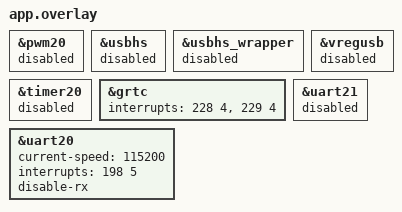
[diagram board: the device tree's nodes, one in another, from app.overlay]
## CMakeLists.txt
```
cmake_minimum_required(VERSION 3.20.0)

# NCS 3.4.1 needs Seeed's external board definitions for this XIAO.
# Board roots must be added before find_package(Zephyr).
list(APPEND BOARD_ROOT
    "${CMAKE_CURRENT_SOURCE_DIR}/../../third_party/platform-seeedboards/zephyr/nrf"
)

# NCS 3.4.1's nrf_security caches these strings without Kconfig quotes.
# On reconfigure, Zephyr mistakes them for command-line Kconfig overrides.
# Discard those malformed entries; Kconfig reloads the configured values.
# Preserve correctly quoted overrides supplied explicitly by the user.
foreach(symbol IN ITEMS
    CONFIG_MBEDTLS_CONFIG_FILE
    CONFIG_TF_PSA_CRYPTO_CONFIG_FILE
    CONFIG_TF_PSA_CRYPTO_USER_CONFIG_FILE
)
    if(DEFINED CACHE{${symbol}} AND NOT "$CACHE{${symbol}}" MATCHES "^\".*\"$")
        unset(${symbol} CACHE)
    endif()
endforeach()

find_package(Zephyr REQUIRED HINTS $ENV{ZEPHYR_BASE})
project(xiao_wireless_benchmark)

target_include_directories(app PRIVATE include)
target_sources(app PRIVATE
    src/main.c
    src/esb_transport.c
    src/link_state_machine.c
    src/benchmark.c
    src/status_telemetry.c
)
# Treat application warnings as errors without imposing this on the Nordic SDK.
target_compile_options(app PRIVATE -Wall -Wextra -Werror)
```

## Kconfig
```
mainmenu "XIAO 4 Mbit/s ESB benchmark"

# Seeed also declares UART_CONSOLE outside Zephyr's CONSOLE menu, with a
# default of y when SERIAL is enabled. With CONSOLE=n its user prompt is
# hidden, so prj.conf alone cannot override that default. Put this default
# first to keep the dedicated telemetry UART free of a console backend.
config UART_CONSOLE
	default n

source "Kconfig.zephyr"

choice BENCHMARK_ROLE

	prompt "Role of this board"
	default BENCHMARK_TRANSMITTER

config BENCHMARK_TRANSMITTER
	bool "Mouse-side transmitter (PTX)"

config BENCHMARK_RECEIVER
	bool "Dongle-side receiver (PRX)"

endchoice

config BENCHMARK_RF_CHANNEL
	int "Fixed ESB RF channel (2400 MHz + channel)"
	range 0 80
	default 40
	help
	  Both builds must use the same channel. This evaluation has no hopping,
	  encryption, or production pairing; keep unrelated test pairs apart.
```

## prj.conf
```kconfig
# The application owns the radio. Bluetooth and USB are not part of this test.
CONFIG_ESB=y
CONFIG_ESB_CLOCK_INIT=y
CONFIG_CLOCK_CONTROL=y
CONFIG_ESB_MAX_PAYLOAD_LENGTH=32
CONFIG_ESB_PIPE_COUNT=1
CONFIG_ESB_TX_FIFO_SIZE=8
CONFIG_ESB_RX_FIFO_SIZE=16
CONFIG_ESB_SYS_TIMER10=y
CONFIG_NRFX_TIMER=y

# Keep symbols and useful locals for RAM inspection. Do not benchmark while halted.
CONFIG_DEBUG_OPTIMIZATIONS=y
CONFIG_DEBUG_THREAD_INFO=y
CONFIG_ASSERT=y
CONFIG_MAIN_STACK_SIZE=4096
CONFIG_GPIO=y
CONFIG_ENTROPY_GENERATOR=y

# Keep CPU/peripheral wake latency short during this timing experiment. This
# consumes extra power: these measurements are not a battery-life benchmark.
CONFIG_SOC_NRF_FORCE_CONSTLAT=y
CONFIG_NRF_SYS_EVENT=y
CONFIG_NRF_SYS_EVENT_GRTC_CHAN_CNT=0

# Low-rate status uses UART20 EasyDMA directly, outside the radio callbacks.
# Keep its pins/peripheral active to avoid repeated IRQ-locked power transitions.
CONFIG_SERIAL=y
CONFIG_UART_ASYNC_API=y
CONFIG_UART_20_ASYNC=y
CONFIG_UART_20_NRF_ASYNC_LOW_POWER=n
# No per-packet logging: its cost would swamp a 125 us schedule.
CONFIG_LOG=n
# UART20 has one owner. Do not let a console/log backend interleave bytes.
CONFIG_CONSOLE=n
CONFIG_UART_CONSOLE=n
```

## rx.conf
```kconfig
# Flash this image onto the dongle-side evaluation board.
CONFIG_BENCHMARK_RECEIVER=y
```

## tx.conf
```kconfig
# Flash this image onto the mouse-side evaluation board.
CONFIG_BENCHMARK_TRANSMITTER=y
```

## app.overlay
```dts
/* The blue LED is a GPIO heartbeat; no PWM driver should claim it. */
&pwm20 {
	status = "disabled";
};

/* V1.0 has no Nordic USB connection. The SAMD11 remains the debug bridge. */
&usbhs {
	status = "disabled";
};
&usbhs_wrapper {
	status = "disabled";
};
&vregusb {
	status = "disabled";
};

/* TIMER20 is accessed directly through nrfx, so leave its Zephyr driver off.
 * ESB owns TIMER10; the operating system owns GRTC. Do not share those timers.
 */
&timer20 {
	status = "disabled";
};

/* On this SoC the application's GRTC IRQs are GRTC_2/3 (228/229).
 * Keep kernel clock bookkeeping below RADIO (1), ESB events (2), and our
 * cadence timer (3), so a control-thread wakeup cannot needlessly delay RF.
 */
&grtc {
	interrupts = <228 4>, <229 4>;
};

/* V1.0 UART20 is wired through a level shifter to the SAMD11 USB-CDC bridge.
 * Its low-priority DMA completion must not preempt radio/cadence/clock work.
 * This telemetry module only transmits; it never starts a UART RX DMA/timer.
 */
&uart20 {
	status = "okay";
	current-speed = <115200>;
	interrupts = <198 5>;
	disable-rx;
};

/* UART21 is the separate D6/D7 header UART, unused in this experiment. */
&uart21 {
	status = "disabled";
};
```

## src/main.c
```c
#include <zephyr/drivers/gpio.h>
#include <zephyr/kernel.h>

#include "link_state_machine.h"
#include "status_telemetry.h"

static const struct gpio_dt_spec led = GPIO_DT_SPEC_GET(DT_ALIAS(led0), gpios);

/* Keep main as glue: modules own radio, connection management, and measurements.
 * The slow heartbeat remains visible without opening a serial monitor.
 * A solid LED indicates an initialization/runtime fault.
 */
int main(void)
{
	bool led_ready = gpio_is_ready_dt(&led) &&
			 gpio_pin_configure_dt(&led, GPIO_OUTPUT_INACTIVE) == 0;
	int telemetry_error = status_telemetry_init();
	int err = link_state_machine_init();
	uint32_t last_toggle_ms = 0;
	bool illuminated = false;

	while (true) {
		if (err == 0) {
			link_state_machine_process();
		}
		if (telemetry_error == 0) {
			status_telemetry_process();
		}
		uint32_t now_ms = k_uptime_get_32();

		if (led_ready && (now_ms - last_toggle_ms >= 500U)) {
			last_toggle_ms = now_ms;
			illuminated = !illuminated;
			gpio_pin_set_dt(&led, telemetry_error != 0 ||
				       g_link_status.state == LINK_FAULT ||
				       illuminated);
		}
		/* This sleep services only slow control. TIMER20 schedules data. */
		k_msleep(10);
	}
	return 0;
}
```

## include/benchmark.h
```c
#ifndef WIRELESS_BENCHMARK_H_
#define WIRELESS_BENCHMARK_H_

#include <stdbool.h>
#include <stdint.h>

#ifdef __cplusplus
extern "C" {
#endif

#define BENCHMARK_RESULT_CAPACITY 25U
#define BENCHMARK_PACKET_COUNT 1000000U
#define BENCHMARK_PERIOD_US 125U
#define BENCHMARK_PAYLOAD_BYTES 16U
#define BENCHMARK_LATE_THRESHOLD_US 10U
#define BENCHMARK_GAP_BUCKETS 6U

/*
 * One run's debugger-friendly summary. Counters are 64-bit so arithmetic such
 * as packet_count * 1,000,000 does not overflow a 32-bit intermediate.
 *
 * The receiver accepts increasing sequence numbers. ESB preserves packet
 * order, so an equal sequence is a duplicate and an older sequence is counted
 * as out-of-order/late. This deliberately avoids a million-packet bitmap.
 *
 * Time values are LOCAL software callback timestamps in microseconds, not
 * synchronized clocks or hardware measurements of radio airtime/latency.
 */
struct benchmark_result {
	uint32_t run_id;
	uint32_t expected_packets;
	uint32_t first_sequence;
	uint32_t last_sequence;
	uint8_t transmitter;
	uint8_t completed;
	uint16_t reserved;
	uint64_t first_activity_us;
	uint64_t last_activity_us;
	uint64_t elapsed_us;

	uint64_t tx_scheduled_slots;
	uint64_t tx_submitted_packets;
	uint64_t tx_busy_drops;
	uint64_t tx_submit_errors;
	uint64_t tx_successes;
	uint64_t tx_failures;
	uint64_t tx_missed_deadlines;
	uint64_t tx_late_slots;
	uint64_t tx_lateness_sum_us;
	uint64_t tx_lateness_max_us;

	uint64_t rx_unique_packets;
	uint64_t rx_duplicate_packets;
	uint64_t rx_out_of_order_packets;
	uint64_t rx_out_of_range_packets;
	/* Live: missing through last_sequence; finished: includes the entire tail. */
	uint64_t rx_missing_packets;
	uint64_t rx_gap_count;
	uint64_t rx_gap_min_us;
	uint64_t rx_gap_max_us;
	uint64_t rx_gap_sum_us;
	/* Buckets: <=125, <=150, <=250, <=500, <=1000, and >1000 us. */
	uint64_t rx_gap_histogram[BENCHMARK_GAP_BUCKETS];

	/*
	 * Cadence is (timestamped_samples - 1) / elapsed: TX opportunities,
	 * including skipped slots, or RX accepted unique packets. millihertz
	 * preserves three decimal places without floating-point code in IRQs.
	 * TX bulk skips use their observation time, so RX cadence is the useful
	 * delivered-packet measurement, especially after a debugger pause.
	 */
	uint64_t packet_rate_millihz;
	/* RX payload goodput excludes the first sample's unobserved interval. */
	uint64_t payload_goodput_bps;
};

/*
 * Result publication uses an odd/even generation: an odd value means finish
 * is publishing; an even value means its result/average/metadata are ready.
 * result_generation[index] == 0 means that ring entry has never been used.
 * Otherwise it is the monotonically increasing recorded-run number.
 */
struct benchmark_metadata {
	uint32_t publication_generation;
	uint32_t write_index;
	uint32_t valid_results;
	uint32_t running;
	uint64_t runs_recorded;
	uint64_t runs_completed;
	uint64_t average_count;
	uint64_t result_generation[BENCHMARK_RESULT_CAPACITY];
};

/*
 * A small, coherent snapshot for periodic status reporting. Per-run counters
 * describe the current run (or its frozen result after finish). tx_total and
 * rx_total count successful data TX and accepted unique RX packets since boot;
 * they survive run changes so a one-second delta remains useful at boundaries.
 * ESB control traffic is deliberately excluded from these packet totals.
 */
struct benchmark_counters {
	uint32_t run_id;
	bool running;
	uint32_t tx_sent;
	uint32_t rx_received;
	uint32_t rx_missing;
	uint32_t tx_busy;
	uint32_t tx_missed;
	uint32_t tx_errors;
	uint64_t tx_total;
	uint64_t rx_total;
	uint64_t recorded_runs;
};

/*
 * These names intentionally remain global and volatile for VS Code/GDB.
 * The ring includes aborted runs. The average includes every completed run
 * since boot, even after its individual ring entry has been overwritten.
 *
 * Every numeric average field is an arithmetic mean of per-run fields:
 * histogram bins, per-run minima/maxima, and derived rates are averaged too.
 * It is NOT a pooled histogram, global extremum, or duration-weighted rate.
 * IDs, sequence numbers, and absolute timestamps are zero in the average;
 * transmitter is 2 if completed runs include both device roles.
 */
extern volatile struct benchmark_result
	g_benchmark_results[BENCHMARK_RESULT_CAPACITY];
extern volatile struct benchmark_result g_benchmark_average;
extern volatile struct benchmark_result g_benchmark_current;
extern volatile struct benchmark_metadata g_benchmark_metadata;

/* Start a run from thread context; expected_packets == 0 leaves it stopped. */
void benchmark_begin(uint32_t run_id, bool transmitter,
		     uint32_t expected_packets);

/* Record one scheduled TX opportunity, even when submitting it failed. */
void benchmark_tx_slot(uint32_t sequence, uint64_t now_us, int submit_result,
		       uint32_t late_us);

/*
 * Record missed opportunities in constant time; no catch-up packets are sent.
 * late_us is lateness of first_sequence at now_us; each subsequent skipped
 * opportunity is one BENCHMARK_PERIOD_US newer. The caller must report each
 * sequence exactly once, either here or through benchmark_tx_slot().
 */
void benchmark_tx_skip(uint32_t first_sequence, uint32_t count,
		       uint64_t now_us, uint32_t late_us);

/* Record ESB completion. With no ACK, success means transmitted, not received. */
void benchmark_tx_complete(bool success);

/* Record one received packet after the caller has validated its run ID. */
void benchmark_rx(uint32_t sequence, uint64_t now_us);

/*
 * Stop and publish from THREAD context after draining transport callbacks.
 * completed means the run reached its agreed end, not that delivery was
 * lossless. now_us is a fallback for a run with no timestamped activity.
 */
void benchmark_finish(bool completed, uint64_t now_us);

/* Return whether callbacks currently contribute to a run. */
bool benchmark_is_running(void);

/* Copy only compact counters under a short IRQ lock; output must be non-NULL. */
void benchmark_get_counters(struct benchmark_counters *counters);

/*
 * Copy the latest recorded run, including aborted runs, without locking IRQs
 * across the large result structure. generation is its recorded-run number.
 * Return false if no result exists or publication overlaps the copy; the caller
 * should retry on its next reporting pass instead of spinning. Both outputs
 * must be non-NULL and remain unchanged on failure.
 */
bool benchmark_get_latest_result(struct benchmark_result *result,
				 uint64_t *generation);

#ifdef __cplusplus
}
#endif

#endif /* WIRELESS_BENCHMARK_H_ */
```

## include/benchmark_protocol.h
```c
#ifndef BENCHMARK_PROTOCOL_H
#define BENCHMARK_PROTOCOL_H

#include <stdbool.h>
#include <stddef.h>
#include <stdint.h>
#include <zephyr/sys/byteorder.h>

#define BENCHMARK_PACKET_COUNT 1000000U
#define BENCHMARK_PERIOD_US 125U
#define BENCHMARK_DATA_SIZE 16U
#define BENCHMARK_CONTROL_SIZE 24U
#define BENCHMARK_PROTOCOL_VERSION 1U

enum benchmark_packet_kind {
	PACKET_HELLO = 1,
	PACKET_READY,
	PACKET_START,
	PACKET_ARMED,
	PACKET_FINISH,
	PACKET_QUERY,
	PACKET_SUMMARY,
	PACKET_MOUSE = 0x80,
};

/* This is an in-memory representation, not an over-the-air C struct. Explicit
 * little-endian encoding avoids padding, alignment, and compiler ABI surprises.
 */
struct benchmark_control {
	enum benchmark_packet_kind kind;
	uint32_t run_id;
	uint32_t received;
	uint32_t missing;
	bool completed;
};

/* Encode the fixed test contract as well as the control message's variable data. */
static inline void benchmark_control_encode(uint8_t *data,
					    const struct benchmark_control *message)
{
	data[0] = message->kind;
	data[1] = BENCHMARK_PROTOCOL_VERSION;
	sys_put_le32(message->run_id, &data[2]);
	sys_put_le32(BENCHMARK_PACKET_COUNT, &data[6]);
	sys_put_le16(BENCHMARK_PERIOD_US, &data[10]);
	data[12] = BENCHMARK_DATA_SIZE;
	data[13] = 4; /* 4 Mbit/s proprietary PHY, not Bluetooth. */
	data[14] = 1; /* Motion packets deliberately request no ACK. */
	sys_put_le32(message->received, &data[15]);
	sys_put_le32(message->missing, &data[19]);
	data[23] = message->completed;
}

/* Reject peers using a different contract before accepting a run or its result. */
static inline bool benchmark_control_decode(const uint8_t *data, size_t length,
					    struct benchmark_control *message)
{
	if (length != BENCHMARK_CONTROL_SIZE || data[0] < PACKET_HELLO ||
	    data[0] > PACKET_SUMMARY || data[1] != BENCHMARK_PROTOCOL_VERSION ||
	    sys_get_le32(&data[6]) != BENCHMARK_PACKET_COUNT ||
	    sys_get_le16(&data[10]) != BENCHMARK_PERIOD_US ||
	    data[12] != BENCHMARK_DATA_SIZE || data[13] != 4 || data[14] != 1 ||
	    data[23] > 1) {
		return false;
	}
	message->kind = data[0];
	message->run_id = sys_get_le32(&data[2]);
	message->received = sys_get_le32(&data[15]);
	message->missing = sys_get_le32(&data[19]);
	message->completed = data[23] != 0;
	return true;
}

/* Create a reproducible spoof mouse report with a 32-bit run and slot sequence.
 * Bytes 9..15 match the seven mouse data bytes in your HID descriptor. The ESB
 * radio appends CRC16 separately; no extra application CRC is needed here.
 */
static inline void benchmark_mouse_encode(uint8_t *data, uint32_t run_id,
					 uint32_t sequence)
{
	data[0] = PACKET_MOUSE;
	sys_put_le32(run_id, &data[1]);
	sys_put_le32(sequence, &data[5]);
	data[9] = (sequence / 8000U) & 0x1fU; /* Five fake buttons. */
	sys_put_le16((uint16_t)(int16_t)((int32_t)(sequence % 201U) - 100), &data[10]);
	sys_put_le16((uint16_t)(int16_t)(100 - (int32_t)(sequence % 201U)), &data[12]);
	data[14] = 0; /* Wheel. */
	data[15] = 0; /* Horizontal pan. */
}

#endif
```

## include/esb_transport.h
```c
/*
 * The transport owns Nordic ESB and its queues. Protocol and benchmark code
 * exchange byte strings here without depending on ESB's payload structures.
 */
#ifndef ESB_TRANSPORT_H_
#define ESB_TRANSPORT_H_

#include <stdbool.h>
#include <stddef.h>
#include <stdint.h>

#define ESB_TRANSPORT_MAX_PAYLOAD 32U

struct esb_transport_callbacks {
	/* Called in ESB event interrupt context; data is valid only in this call. */
	void (*received)(const uint8_t *data, size_t length, uint64_t now_us);
	/* No-ACK success means transmitted, not confirmed reception by the peer. */
	void (*transmitted)(bool success);
};

/* Initialize a fixed PTX or PRX role, 4 Mbps, CRC16 and the test RF address. */
int esb_transport_init(bool transmitter,
		       const struct esb_transport_callbacks *callbacks);

/*
 * Submit one PTX payload. A busy transmitter returns -EBUSY instead of building
 * a queue of old mouse samples. Safe from main or the benchmark timer ISR.
 */
int esb_transport_send(const uint8_t *data, size_t length, bool request_ack);

/*
 * Replace the PRX's next ACK payload during a control phase. The reply is sent
 * in response to a FUTURE request; it cannot amend an ACK already on the air.
 * Retry -EBUSY from main after the current ACK finishes. This operation briefly
 * pauses reception and must not be called during a timed data run.
 */
int esb_transport_receiver_queue_reply(const uint8_t *data, size_t length);

/* Return whether a PTX has finished its previous packet and can send another. */
bool esb_transport_is_idle(void);

/* Clear stale packets between control phases; never call during a timed run. */
int esb_transport_reset_queues(void);

#endif /* ESB_TRANSPORT_H_ */
```

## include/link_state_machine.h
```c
#ifndef LINK_STATE_MACHINE_H
#define LINK_STATE_MACHINE_H

#include <stdbool.h>
#include <stdint.h>

enum link_state {
	LINK_BOOT,
	LINK_DISCOVERING,
	LINK_NEGOTIATING,
	LINK_ARMED,
	LINK_RUNNING,
	LINK_DRAINING,
	LINK_WAIT_SUMMARY,
	LINK_PAUSE,
	LINK_FAULT,
};

/* Deliberately public debugger view. Operational state remains private to the
 * module. Pause before inspecting 64-bit fields on this 32-bit CPU.
 */
struct link_debug_status {
	enum link_state state;
	bool transmitter;
	uint32_t run_id;
	int last_error;
	uint32_t rejected_packets;
	uint32_t control_queue_overflows;
	uint32_t control_tx_failures;
	uint32_t reconnects;
	uint32_t next_sequence;
	uint32_t remote_received;
	uint32_t remote_missing;
	bool remote_completed;
	bool remote_summary_valid;
	uint64_t last_data_rx_us;
};

extern volatile struct link_debug_status g_link_status;

/* Initialize the fixed PTX/PRX role selected by this image's Kconfig. */
int link_state_machine_init(void);

/* Service control traffic and timeouts from the main thread, about every 10 ms. */
void link_state_machine_process(void);

/* Copy the compact debugger view coherently while radio callbacks are active. */
void link_state_machine_get_status(struct link_debug_status *status);

#endif
```

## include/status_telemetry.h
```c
#ifndef STATUS_TELEMETRY_H_
#define STATUS_TELEMETRY_H_

#include <stdbool.h>

/* Debugger switch for comparing RF performance with reporting enabled/disabled.
 * An already queued DMA line may finish after this is cleared. No reset needed.
 */
extern volatile bool g_status_telemetry_enabled;

/* Initialize the SAMD11 bridge UART for asynchronous, transmit-only status. */
int status_telemetry_init(void);

/* Report state changes, finished runs, and one-second counters from main only. */
void status_telemetry_process(void);

#endif /* STATUS_TELEMETRY_H_ */
```

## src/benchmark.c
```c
#include "benchmark.h"

#include <errno.h>
#include <stddef.h>
#include <string.h>

#include <zephyr/irq.h>

volatile struct benchmark_result g_benchmark_results[BENCHMARK_RESULT_CAPACITY];
volatile struct benchmark_result g_benchmark_average;
volatile struct benchmark_result g_benchmark_current;
volatile struct benchmark_metadata g_benchmark_metadata;

/*
 * A separate exact sum prevents recursive integer averaging from steadily
 * rounding the running average toward zero. All divisions happen at finish,
 * outside the time-sensitive radio/timer callbacks.
 */
#define AVERAGED_FIELDS(X)                   \
	X(expected_packets)                  \
	X(elapsed_us)                        \
	X(tx_scheduled_slots)                \
	X(tx_submitted_packets)              \
	X(tx_busy_drops)                     \
	X(tx_submit_errors)                  \
	X(tx_successes)                      \
	X(tx_failures)                       \
	X(tx_missed_deadlines)               \
	X(tx_late_slots)                     \
	X(tx_lateness_sum_us)                \
	X(tx_lateness_max_us)                \
	X(rx_unique_packets)                \
	X(rx_duplicate_packets)             \
	X(rx_out_of_order_packets)          \
	X(rx_out_of_range_packets)          \
	X(rx_missing_packets)               \
	X(rx_gap_count)                     \
	X(rx_gap_min_us)                    \
	X(rx_gap_max_us)                    \
	X(rx_gap_sum_us)                    \
	X(packet_rate_millihz)              \
	X(payload_goodput_bps)

struct benchmark_totals {
#define DECLARE_TOTAL(field) uint64_t field;
	AVERAGED_FIELDS(DECLARE_TOTAL)
#undef DECLARE_TOTAL
	uint64_t rx_gap_histogram[BENCHMARK_GAP_BUCKETS];
};

static struct benchmark_totals average_totals;
static bool have_activity;
static uint8_t averaged_role;
/* These boot-lifetime totals cannot jump backward when begin resets a run. */
static uint64_t lifetime_tx_successes;
static uint64_t lifetime_rx_unique_packets;

/* Identify one inter-arrival bucket without division or floating point. */
static size_t gap_bucket(uint64_t gap_us)
{
	if (gap_us <= 125U) {
		return 0U;
	}
	if (gap_us <= 150U) {
		return 1U;
	}
	if (gap_us <= 250U) {
		return 2U;
	}
	if (gap_us <= 500U) {
		return 3U;
	}
	if (gap_us <= 1000U) {
		return 4U;
	}
	return 5U;
}

/* Update sample bounds while the caller holds the short IRQ critical section. */
static void record_activity(uint32_t sequence, uint64_t now_us)
{
	if (!have_activity) {
		g_benchmark_current.first_activity_us = now_us;
		g_benchmark_current.first_sequence = sequence;
		have_activity = true;
	}
	g_benchmark_current.last_activity_us = now_us;
	g_benchmark_current.last_sequence = sequence;
	g_benchmark_current.elapsed_us = now_us - g_benchmark_current.first_activity_us;
}

/* Accumulate one slot's scheduling jitter while interrupts are locked. */
static void record_lateness(uint32_t late_us)
{
	g_benchmark_current.tx_lateness_sum_us += late_us;
	if (late_us > g_benchmark_current.tx_lateness_max_us) {
		g_benchmark_current.tx_lateness_max_us = late_us;
	}
	if (late_us > BENCHMARK_LATE_THRESHOLD_US) {
		g_benchmark_current.tx_late_slots++;
	}
}

/* Start with a fresh live summary; history and its all-run average survive. */
void benchmark_begin(uint32_t run_id, bool transmitter,
		     uint32_t expected_packets)
{
	struct benchmark_result fresh = {
		.run_id = run_id,
		.expected_packets = expected_packets,
		.transmitter = transmitter ? 1U : 0U,
	};
	unsigned int key = irq_lock();

	g_benchmark_current = fresh;
	have_activity = false;
	g_benchmark_metadata.running = expected_packets != 0U;
	irq_unlock(key);
}

/* Count an attempted opportunity separately from an accepted ESB submission. */
void benchmark_tx_slot(uint32_t sequence, uint64_t now_us, int submit_result,
		       uint32_t late_us)
{
	unsigned int key = irq_lock();

	if (!g_benchmark_metadata.running || !g_benchmark_current.transmitter) {
		irq_unlock(key);
		return;
	}
	if (sequence >= g_benchmark_current.expected_packets) {
		g_benchmark_current.tx_submit_errors++;
		irq_unlock(key);
		return;
	}
	record_activity(sequence, now_us);
	g_benchmark_current.tx_scheduled_slots++;
	record_lateness(late_us);
	if (submit_result == 0) {
		g_benchmark_current.tx_submitted_packets++;
	} else if (submit_result == -EBUSY || submit_result == -ENOBUFS ||
		   submit_result == -EAGAIN || submit_result == -ENOMEM) {
		/* Nordic ESB reports a full software FIFO as -ENOMEM. */
		g_benchmark_current.tx_busy_drops++;
	} else {
		g_benchmark_current.tx_submit_errors++;
	}
	irq_unlock(key);
}

/* Summarize a missed block arithmetically, rather than looping in a timer IRQ. */
void benchmark_tx_skip(uint32_t first_sequence, uint32_t count,
		       uint64_t now_us, uint32_t late_us)
{
	unsigned int key = irq_lock();
	uint64_t positive_count;
	uint64_t late_count;
	uint64_t lateness_sum;
	uint32_t remaining;

	if (!g_benchmark_metadata.running || !g_benchmark_current.transmitter ||
	    count == 0U || first_sequence >= g_benchmark_current.expected_packets) {
		irq_unlock(key);
		return;
	}
	remaining = g_benchmark_current.expected_packets - first_sequence;
	if (count > remaining) {
		count = remaining;
	}

	/*
	 * Lateness is max(late_us - index * period, 0). Sum the positive
	 * arithmetic progression, using 64-bit products even for long pauses.
	 */
	positive_count = ((uint64_t)late_us + BENCHMARK_PERIOD_US - 1U) /
			 BENCHMARK_PERIOD_US;
	if (positive_count > count) {
		positive_count = count;
	}
	lateness_sum = positive_count * late_us;
	if (positive_count > 0U) {
		lateness_sum -= BENCHMARK_PERIOD_US * positive_count *
				(positive_count - 1U) / 2U;
	}
	late_count = late_us > BENCHMARK_LATE_THRESHOLD_US ?
		((uint64_t)late_us - BENCHMARK_LATE_THRESHOLD_US +
		 BENCHMARK_PERIOD_US - 1U) / BENCHMARK_PERIOD_US : 0U;
	if (late_count > count) {
		late_count = count;
	}
	if (!have_activity) {
		/* The first observed block still identifies its earliest sequence. */
		record_activity(first_sequence, now_us);
	}
	record_activity(first_sequence + count - 1U, now_us);
	g_benchmark_current.tx_scheduled_slots += count;
	g_benchmark_current.tx_missed_deadlines += count;
	g_benchmark_current.tx_late_slots += late_count;
	g_benchmark_current.tx_lateness_sum_us += lateness_sum;
	if (late_us > g_benchmark_current.tx_lateness_max_us) {
		g_benchmark_current.tx_lateness_max_us = late_us;
	}
	irq_unlock(key);
}

/* ESB no-ACK success proves only that a packet left this transmitter. */
void benchmark_tx_complete(bool success)
{
	unsigned int key = irq_lock();

	if (g_benchmark_metadata.running && g_benchmark_current.transmitter) {
		if (success) {
			g_benchmark_current.tx_successes++;
			lifetime_tx_successes++;
		} else {
			g_benchmark_current.tx_failures++;
		}
	}
	irq_unlock(key);
}

/* Count ordered unique deliveries and their local callback-to-callback gaps. */
void benchmark_rx(uint32_t sequence, uint64_t now_us)
{
	unsigned int key = irq_lock();
	uint64_t gap_us;

	if (!g_benchmark_metadata.running || g_benchmark_current.transmitter) {
		irq_unlock(key);
		return;
	}
	if (sequence >= g_benchmark_current.expected_packets) {
		g_benchmark_current.rx_out_of_range_packets++;
		irq_unlock(key);
		return;
	}
	if (have_activity && sequence <= g_benchmark_current.last_sequence) {
		if (sequence == g_benchmark_current.last_sequence) {
			g_benchmark_current.rx_duplicate_packets++;
		} else {
			/* Older retransmissions cannot be distinguished from reordering. */
			g_benchmark_current.rx_out_of_order_packets++;
		}
		irq_unlock(key);
		return;
	}
	if (have_activity) {
		gap_us = now_us - g_benchmark_current.last_activity_us;
		if (g_benchmark_current.rx_gap_count == 0U ||
		    gap_us < g_benchmark_current.rx_gap_min_us) {
			g_benchmark_current.rx_gap_min_us = gap_us;
		}
		if (gap_us > g_benchmark_current.rx_gap_max_us) {
			g_benchmark_current.rx_gap_max_us = gap_us;
		}
		g_benchmark_current.rx_gap_count++;
		g_benchmark_current.rx_gap_sum_us += gap_us;
		g_benchmark_current.rx_gap_histogram[gap_bucket(gap_us)]++;
	}
	record_activity(sequence, now_us);
	g_benchmark_current.rx_unique_packets++;
	lifetime_rx_unique_packets++;
	/* During a run only losses up through the newest received sequence are
	 * knowable. finish() adds the unreceived tail of the agreed packet count.
	 */
	g_benchmark_current.rx_missing_packets = (uint64_t)sequence + 1U -
						g_benchmark_current.rx_unique_packets;
	irq_unlock(key);
}

/* Derive rates once per run, keeping integer division outside radio IRQs. */
static void finalize_result(struct benchmark_result *result)
{
	uint64_t samples = result->transmitter ? result->tx_scheduled_slots :
						 result->rx_unique_packets;

	result->elapsed_us = result->last_activity_us - result->first_activity_us;
	if (!result->transmitter) {
		/* Includes losses before the first and after the last received packet. */
		result->rx_missing_packets = result->expected_packets -
					    result->rx_unique_packets;
	}
	if (samples > 1U && result->elapsed_us > 0U) {
		/* samples is bounded by the 32-bit expected count, so these fit. */
		result->packet_rate_millihz = (samples - 1U) * UINT64_C(1000000000) /
					    result->elapsed_us;
		if (!result->transmitter) {
			result->payload_goodput_bps = (samples - 1U) *
				BENCHMARK_PAYLOAD_BYTES * 8U * UINT64_C(1000000) /
				result->elapsed_us;
		}
	}
}

/* Add exact totals and return the arithmetic mean of completed run summaries. */
static struct benchmark_result update_average(const struct benchmark_result *result,
					     uint64_t count)
{
	struct benchmark_result average = { .completed = 1U };

	if (count == 1U) {
		averaged_role = result->transmitter;
	} else if (averaged_role != result->transmitter) {
		averaged_role = 2U;
	}
	average.transmitter = averaged_role;
#define ADD_AND_AVERAGE(field)                       \
	average_totals.field += result->field;        \
	average.field = average_totals.field / count;
	AVERAGED_FIELDS(ADD_AND_AVERAGE)
#undef ADD_AND_AVERAGE
	for (size_t index = 0U; index < BENCHMARK_GAP_BUCKETS; index++) {
		average_totals.rx_gap_histogram[index] += result->rx_gap_histogram[index];
		average.rx_gap_histogram[index] =
			average_totals.rx_gap_histogram[index] / count;
	}
	return average;
}

/* Freeze live counters, then publish one ring entry and its all-history mean. */
void benchmark_finish(bool completed, uint64_t now_us)
{
	struct benchmark_result result;
	struct benchmark_result average;
	uint64_t recorded_runs;
	uint64_t completed_runs;
	uint32_t index;
	unsigned int key = irq_lock();

	if (!g_benchmark_metadata.running) {
		irq_unlock(key);
		return;
	}
	g_benchmark_metadata.running = false;
	result = g_benchmark_current;
	if (!have_activity) {
		result.first_activity_us = now_us;
		result.last_activity_us = now_us;
	}
	irq_unlock(key);

	result.completed = completed ? 1U : 0U;
	finalize_result(&result);
	recorded_runs = g_benchmark_metadata.runs_recorded + 1U;
	completed_runs = g_benchmark_metadata.runs_completed + (completed ? 1U : 0U);
	if (completed) {
		average = update_average(&result, completed_runs);
	}

	/*
	 * No callbacks can mutate this stopped run. Publication may copy with
	 * interrupts enabled; debugger consumers check for an even generation
	 * before interpreting a snapshot taken inside this function.
	 */
	g_benchmark_metadata.publication_generation++;
	index = g_benchmark_metadata.write_index;
	g_benchmark_metadata.result_generation[index] = 0U;
	g_benchmark_results[index] = result;
	g_benchmark_current = result;
	if (completed) {
		g_benchmark_average = average;
	}
	g_benchmark_metadata.result_generation[index] = recorded_runs;
	/* The compact telemetry snapshot also reads this 64-bit value on a 32-bit
	 * CPU. Protect this small store so a reporting thread cannot see half of it.
	 */
	key = irq_lock();
	g_benchmark_metadata.runs_recorded = recorded_runs;
	irq_unlock(key);
	g_benchmark_metadata.runs_completed = completed_runs;
	g_benchmark_metadata.average_count = completed_runs;
	g_benchmark_metadata.write_index = (index + 1U) % BENCHMARK_RESULT_CAPACITY;
	if (g_benchmark_metadata.valid_results < BENCHMARK_RESULT_CAPACITY) {
		g_benchmark_metadata.valid_results++;
	}
	g_benchmark_metadata.publication_generation++;
}

/* Read the shared running flag consistently on the single application CPU. */
bool benchmark_is_running(void)
{
	unsigned int key = irq_lock();
	bool running = g_benchmark_metadata.running != 0U;

	irq_unlock(key);
	return running;
}

/* Keep status reporting out of the large per-run summary's IRQ-locked copy. */
void benchmark_get_counters(struct benchmark_counters *counters)
{
	unsigned int key = irq_lock();

	counters->run_id = g_benchmark_current.run_id;
	counters->running = g_benchmark_metadata.running != 0U;
	/* Each normal run has at most one million data slots/packets, so its
	 * counters fit in 32 bits. Lifetime totals remain 64-bit across runs.
	 */
	counters->tx_sent = (uint32_t)g_benchmark_current.tx_successes;
	counters->rx_received = (uint32_t)g_benchmark_current.rx_unique_packets;
	counters->rx_missing = (uint32_t)g_benchmark_current.rx_missing_packets;
	counters->tx_busy = (uint32_t)g_benchmark_current.tx_busy_drops;
	counters->tx_missed = (uint32_t)g_benchmark_current.tx_missed_deadlines;
	counters->tx_errors = (uint32_t)(g_benchmark_current.tx_submit_errors +
					 g_benchmark_current.tx_failures);
	counters->tx_total = lifetime_tx_successes;
	counters->rx_total = lifetime_rx_unique_packets;
	counters->recorded_runs = g_benchmark_metadata.runs_recorded;
	irq_unlock(key);
}

/* Use the publication generation to reject a large copy interrupted by finish. */
bool benchmark_get_latest_result(struct benchmark_result *result,
				 uint64_t *generation)
{
	struct benchmark_result snapshot;
	uint64_t recorded_generation;
	uint32_t before = g_benchmark_metadata.publication_generation;
	uint32_t index;
	uint32_t after;

	if ((before & 1U) != 0U || g_benchmark_metadata.valid_results == 0U) {
		return false;
	}
	index = (g_benchmark_metadata.write_index + BENCHMARK_RESULT_CAPACITY - 1U) %
		BENCHMARK_RESULT_CAPACITY;
	snapshot = g_benchmark_results[index];
	recorded_generation = g_benchmark_metadata.result_generation[index];
	after = g_benchmark_metadata.publication_generation;
	/* All shared publication fields are volatile. If a publisher ran during
	 * this interruptible copy, ignore even a plausible-looking partial result.
	 */
	if (before != after || (after & 1U) != 0U || recorded_generation == 0U) {
		return false;
	}
	*result = snapshot;
	*generation = recorded_generation;
	return true;
}
```

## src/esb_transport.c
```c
/*
 * A deliberately small ESB adapter: one radio owner, one outstanding PTX
 * payload, no allocation, and no logging in either radio interrupt path.
 */
#include "esb_transport.h"

#include <errno.h>
#include <string.h>

#include <esb.h>
#include <hal/nrf_radio.h>
#include <zephyr/irq.h>
#include <zephyr/kernel.h>
#include <zephyr/sys/util.h>

BUILD_ASSERT(CONFIG_ESB_MAX_PAYLOAD_LENGTH >= ESB_TRANSPORT_MAX_PAYLOAD,
	     "The transport requires 32-byte ESB payload storage");
BUILD_ASSERT(CONFIG_ESB_TX_FIFO_SIZE >= 2,
	     "Replacing ACK payloads requires two ESB TX FIFO entries");

static struct esb_transport_callbacks transport_callbacks;
static bool transport_initialized;
static bool transport_transmitter;
static bool transport_tx_busy;

/* Convert the kernel's 64-bit hardware cycle counter to monotonic microseconds. */
static uint64_t transport_now_us(void)
{
	/* On this board the cycle source is GRTC, not the CPU clock or SysTick. */
	return k_cyc_to_us_floor64(k_cycle_get_64());
}

/* Replace an ACK only while the PRX is unambiguously in a receive state. */
static bool receiver_ack_in_progress(void)
{
	nrf_radio_state_t state = nrf_radio_state_get(NRF_RADIO);

	/* Include disable/disabled transitions: hardware shorts may already be
	 * about to ramp TX before the higher-priority radio IRQ has run.
	 */
	return state != NRF_RADIO_STATE_RXRU &&
	       state != NRF_RADIO_STATE_RXIDLE &&
	       state != NRF_RADIO_STATE_RX;
}

/* Deliver short notifications and completely drain ESB's coalesced RX event. */
static void transport_event_handler(const struct esb_evt *event)
{
	switch (event->evt_id) {
	case ESB_EVENT_TX_SUCCESS:
	case ESB_EVENT_TX_FAILED:
		/* PRX also reports TX_SUCCESS when an ACK payload is retired. That
		 * notification does not complete a benchmark transmission.
		 */
		if (transport_transmitter) {
			unsigned int key = irq_lock();
			bool success = event->evt_id == ESB_EVENT_TX_SUCCESS;

			if (!success) {
				/* ESB retains a failed reliable packet at the FIFO head.
				 * Remove it before admitting the next control packet.
				 * ESB sets itself IDLE before issuing TX_FAILED.
				 */
				(void)esb_flush_tx();
			}
			transport_tx_busy = false;
			irq_unlock(key);

			if (transport_callbacks.transmitted != NULL) {
				transport_callbacks.transmitted(success);
			}
		}
		break;

	case ESB_EVENT_RX_RECEIVED: {
		struct esb_payload payload;

		/* ESB event flags are bits, not packet counts: a single callback
		 * can represent several FIFO entries. Always drain the FIFO.
		 */
		while (esb_read_rx_payload(&payload) == 0) {
			uint64_t now_us = transport_now_us();

			if (transport_callbacks.received != NULL) {
				/* This is callback arrival time, not a hardware RF timestamp.
				 * A delayed event IRQ can therefore affect measured jitter.
				 */
				transport_callbacks.received(payload.data, payload.length,
							     now_us);
			}
		}
		break;
	}
	default:
		break;
	}
}

/* Configure both roles identically except for which endpoint initiates a send. */
int esb_transport_init(bool transmitter,
		       const struct esb_transport_callbacks *callbacks)
{
	/* Fixed, intentionally public bench addresses; these are not pairing keys. */
	static const uint8_t base_address_0[4] = {0xA7, 0xC3, 0x56, 0x91};
	static const uint8_t base_address_1[4] = {0xD2, 0x8B, 0x47, 0x69};
	static const uint8_t prefixes[1] = {0xE7};
	struct esb_config config = ESB_DEFAULT_CONFIG;
	int err;

	if (callbacks == NULL) {
		return -EINVAL;
	}
	if (transport_initialized) {
		return -EALREADY;
	}

	transport_callbacks = *callbacks;
	transport_transmitter = transmitter;
	transport_tx_busy = false;
	config.mode = transmitter ? ESB_MODE_PTX : ESB_MODE_PRX;
	config.protocol = ESB_PROTOCOL_ESB_DPL;
	config.bitrate = ESB_BITRATE_4MBPS;
	config.crc = ESB_CRC_16BIT;
	config.selective_auto_ack = true;
	config.use_fast_ramp_up = true;
	config.event_handler = transport_event_handler;
	/* The minimum retransmit delay is validated even for no-ACK data. Keep
	 * the SDK's supported 600 us value; it is not the 125 us data cadence.
	 */
	config.retransmit_delay = 600;
	config.retransmit_count = 3;

	err = esb_init(&config);
	if (err != 0) {
		return err;
	}
	err = esb_set_base_address_0(base_address_0);
	if (err == 0) {
		err = esb_set_base_address_1(base_address_1);
	}
	if (err == 0) {
		err = esb_set_prefixes(prefixes, ARRAY_SIZE(prefixes));
	}
	if (err == 0) {
		err = esb_enable_pipes(BIT(0));
	}
	if (err == 0) {
		err = esb_set_rf_channel(CONFIG_BENCHMARK_RF_CHANNEL);
	}
	if (err == 0 && !transmitter) {
		err = esb_start_rx();
	}
	if (err != 0) {
		esb_disable();
		return err;
	}
	transport_initialized = true;
	return 0;
}

/* Copy one sample into ESB only when there is no older sample waiting to send. */
int esb_transport_send(const uint8_t *data, size_t length, bool request_ack)
{
	struct esb_payload payload = {0};
	unsigned int key;
	int err;

	if (!transport_initialized || !transport_transmitter) {
		return -EACCES;
	}
	if (data == NULL || length == 0 || length > ESB_TRANSPORT_MAX_PAYLOAD) {
		return -EINVAL;
	}
	payload.pipe = 0;
	payload.length = length;
	payload.noack = !request_ack;
	memcpy(payload.data, data, length);

	/* Main and the cadence ISR both call this API. A single critical section
	 * makes the busy test, ownership change and ESB queue insertion atomic.
	 * Radio/event IRQs stay masked only while copying this small payload.
	 */
	key = irq_lock();
	if (transport_tx_busy || !esb_is_idle()) {
		irq_unlock(key);
		return -EBUSY;
	}
	transport_tx_busy = true;
	err = esb_write_payload(&payload);
	if (err != 0) {
		transport_tx_busy = false;
	}
	irq_unlock(key);
	return err;
}

/* Replace stale PRX ACK contents without interrupting an ACK already on air. */
int esb_transport_receiver_queue_reply(const uint8_t *data, size_t length)
{
	struct esb_payload payload = {0};
	unsigned int key;
	int err;
	int restart_err;

	if (!transport_initialized || transport_transmitter) {
		return -EACCES;
	}
	if (data == NULL || length == 0 || length > ESB_TRANSPORT_MAX_PAYLOAD) {
		return -EINVAL;
	}
	payload.pipe = 0;
	payload.length = length;
	memcpy(payload.data, data, length);

	key = irq_lock();
	if (receiver_ack_in_progress()) {
		irq_unlock(key);
		return -EBUSY;
	}
	/* ESB permits queue flushes only in IDLE. PRX normally listens forever,
	 * so a bounded control-phase pause is required before replacing a reply.
	 */
	err = esb_stop_rx();
	if (err == -EALREADY) {
		err = 0;
	}
	if (err == 0) {
		err = esb_flush_tx();
	}
	if (err == 0) {
		err = esb_write_payload(&payload);
	}
	if (err == 0) {
		/* Counter-intuitively, ESB's flush does not clear its per-pipe
		 * "previous ACK carried data" flag. The next NEW request may
		 * retire one queue head before selecting its reply. Two identical
		 * copies make the replacement valid whether that flag is set or
		 * clear; protocol tokens let the peer ignore repeated replies.
		 */
		err = esb_write_payload(&payload);
	}
	restart_err = esb_start_rx();
	irq_unlock(key);
	return err != 0 ? err : restart_err;
}

/* Snapshot the transport's PTX ownership and ESB state as one coherent test. */
bool esb_transport_is_idle(void)
{
	unsigned int key = irq_lock();
	bool idle = transport_initialized && transport_transmitter &&
		    !transport_tx_busy && esb_is_idle();

	irq_unlock(key);
	return idle;
}

/* Empty queues after a completed/aborted run so the next run starts cleanly. */
int esb_transport_reset_queues(void)
{
	unsigned int key;
	int err;
	int restart_err = 0;

	if (!transport_initialized) {
		return -EACCES;
	}
	key = irq_lock();
	if (transport_tx_busy ||
	    (transport_transmitter && !esb_is_idle()) ||
	    (!transport_transmitter && receiver_ack_in_progress())) {
		irq_unlock(key);
		return -EBUSY;
	}
	err = transport_transmitter ? 0 : esb_stop_rx();
	if (err == -EALREADY) {
		err = 0;
	}
	if (err == 0) {
		err = esb_flush_tx();
	}
	if (err == 0) {
		err = esb_flush_rx();
	}
	if (!transport_transmitter) {
		restart_err = esb_start_rx();
	}
	irq_unlock(key);
	return err != 0 ? err : restart_err;
}
```

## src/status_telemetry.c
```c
#include "status_telemetry.h"

#include <errno.h>
#include <inttypes.h>
#include <stddef.h>
#include <zephyr/device.h>
#include <zephyr/drivers/uart.h>
#include <zephyr/kernel.h>
#include <zephyr/sys/atomic.h>
#include <zephyr/sys/printk.h>

#include "benchmark.h"
#include "link_state_machine.h"

#define STATUS_PERIOD_US 1000000ULL
#define STATUS_BUFFER_SIZE 512U

volatile bool g_status_telemetry_enabled = true;

static const struct device *const uart = DEVICE_DT_GET(DT_NODELABEL(uart20));
static const char *const role = IS_ENABLED(CONFIG_BENCHMARK_TRANSMITTER) ?
			       "TX" : "RX";
/* EasyDMA reads this RAM until TX_DONE/TX_ABORTED. Never reuse it while busy. */
static char tx_buffer[STATUS_BUFFER_SIZE];
static atomic_t tx_busy;
static atomic_t tx_aborts;
static uint32_t tx_submit_errors;
static bool banner_sent;
static bool state_reported;
static enum link_state reported_state;
static uint32_t reported_run;
static uint64_t reported_result;
static uint32_t reported_publication;
static uint64_t previous_time_us;
static uint64_t started_us;
static uint64_t previous_tx_total;
static uint64_t previous_rx_total;

/* DMA completion only releases ownership; all formatting stays in main. */
static void uart_event(const struct device *device, struct uart_event *event,
		       void *context)
{
	ARG_UNUSED(device);
	ARG_UNUSED(context);
	if (event->type == UART_TX_ABORTED) {
		atomic_inc(&tx_aborts);
	}
	if (event->type == UART_TX_DONE || event->type == UART_TX_ABORTED) {
		atomic_clear(&tx_busy);
	}
}

/* Give bounds-checked text to DMA without waiting for a host or a free UART. */
static bool send_line(int length)
{
	if (length <= 0 || (size_t)length >= sizeof(tx_buffer)) {
		tx_submit_errors++;
		return false;
	}
	/* Set ownership before submission: completion can interrupt uart_tx(). */
	atomic_set(&tx_busy, 1);
	int err = uart_tx(uart, (const uint8_t *)tx_buffer, (size_t)length,
			 SYS_FOREVER_US);

	if (err != 0) {
		atomic_clear(&tx_busy);
		tx_submit_errors++;
		return false;
	}
	return true;
}

/* Use readable names without indexing beyond the enum on a faulted device. */
static const char *state_name(enum link_state state)
{
	static const char *const names[] = {
		"BOOT", "DISCOVERING", "NEGOTIATING", "ARMED", "RUNNING",
		"DRAINING", "WAIT_SUMMARY", "PAUSE", "FAULT",
	};

	return (unsigned int)state < ARRAY_SIZE(names) ? names[state] : "UNKNOWN";
}

/* Queue an immutable, end-of-run summary before the next periodic status. */
static bool report_result(const struct benchmark_result *result,
			  uint64_t generation)
{
	int length = snprintk(tx_buffer, sizeof(tx_buffer),
		"[%s] RESULT #=%" PRIu64 " run=%08" PRIX32
		" complete=%u tx=%" PRIu64 " rx=%" PRIu64 " lost=%" PRIu64
		" busy=%" PRIu64 " missed=%" PRIu64 " errors=%" PRIu64
		" rate=%" PRIu64 ".%03" PRIu64 "/s max_gap_us=%" PRIu64
		" max_late_us=%" PRIu64 "\r\n",
		role, generation, result->run_id, (unsigned int)result->completed,
		result->tx_successes, result->rx_unique_packets,
		result->rx_missing_packets, result->tx_busy_drops,
		result->tx_missed_deadlines,
		result->tx_submit_errors + result->tx_failures,
		result->packet_rate_millihz / 1000U,
		result->packet_rate_millihz % 1000U, result->rx_gap_max_us,
		result->tx_lateness_max_us);

	return send_line(length);
}

/* Set up TX-only EasyDMA. A missing serial host never prevents radio startup. */
int status_telemetry_init(void)
{
	if (!device_is_ready(uart)) {
		return -ENODEV;
	}
	previous_time_us = k_cyc_to_us_floor64(k_cycle_get_64());
	/* The hardware GRTC counter can survive a core reset. Display time since
	 * this application initialized instead of that counter's absolute value.
	 */
	started_us = previous_time_us;
	return uart_callback_set(uart, uart_event, NULL);
}

/* Report at most one DMA frame per pass, with no queues or blocking calls. */
void status_telemetry_process(void)
{
	struct link_debug_status link;
	struct benchmark_counters counters;
	uint64_t now_us;
	int length;

	if (!g_status_telemetry_enabled || atomic_get(&tx_busy)) {
		return;
	}
	now_us = k_cyc_to_us_floor64(k_cycle_get_64());
	/* Most 10 ms passes need no report. These atomic-width volatile reads
	 * are only change hints; the coherent snapshots below supply the text.
	 * This avoids masking radio interrupts 100 times/second just to discover
	 * unchanged status. An ISR transition after this check is seen next pass.
	 */
	if (banner_sent && state_reported &&
	    g_link_status.state == reported_state &&
	    g_link_status.run_id == reported_run &&
	    g_benchmark_metadata.publication_generation == reported_publication &&
	    now_us - previous_time_us < STATUS_PERIOD_US) {
		return;
	}
	link_state_machine_get_status(&link);
	benchmark_get_counters(&counters);

	if (!banner_sent) {
		length = snprintk(tx_buffer, sizeof(tx_buffer),
			"[%s] XIAO V1 UART20 115200 8N1; ESB 4M; period_us=%u; "
			"status_ms=1000; lost=sequence gaps; TX success != delivery\r\n",
			role, BENCHMARK_PERIOD_US);
		banner_sent = send_line(length);
		return;
	}
	if (counters.recorded_runs > reported_result) {
		struct benchmark_result result;
		uint64_t generation;

		/* The large result is copied without an IRQ lock. A publication
		 * overlap is retried on the next main pass, never in a busy loop.
		 */
		if (benchmark_get_latest_result(&result, &generation) &&
		    report_result(&result, generation)) {
			reported_result = generation;
			/* Only main publishes results, so this generation cannot
			 * advance between the result snapshot and this assignment.
			 */
			reported_publication =
				g_benchmark_metadata.publication_generation;
		}
		return;
	}
	if (!state_reported || link.state != reported_state ||
	    link.run_id != reported_run) {
		length = snprintk(tx_buffer, sizeof(tx_buffer),
			"[%s] LINK state=%s run=%08" PRIX32 " error=%d reconnects=%"
			PRIu32 " peer_last_rx=%" PRIu32 " peer_last_lost=%" PRIu32
			" peer_summary_valid=%u\r\n", role, state_name(link.state),
			link.run_id, link.last_error, link.reconnects,
			link.remote_received, link.remote_missing,
			(unsigned int)link.remote_summary_valid);
		if (send_line(length)) {
			state_reported = true;
			reported_state = link.state;
			reported_run = link.run_id;
		}
		return;
	}
	uint64_t elapsed_us = now_us - previous_time_us;

	if (elapsed_us < STATUS_PERIOD_US) {
		return;
	}
	/* Lifetime totals never reset at a run boundary. Divide by the actual
	 * sample window: the 10 ms main loop is intentionally not a precise clock.
	 * These rates count data only, excluding HELLO/ACK/FINISH control traffic.
	 */
	uint64_t tx_rate = (counters.tx_total - previous_tx_total) * 1000000ULL /
			   elapsed_us;
	uint64_t rx_rate = (counters.rx_total - previous_rx_total) * 1000000ULL /
			   elapsed_us;

	length = snprintk(tx_buffer, sizeof(tx_buffer),
		"[%s] t=%" PRIu64 "s state=%s run=%08" PRIX32
		" window_ms=%" PRIu64 " tx/s=%" PRIu64 " rx/s=%" PRIu64
		" tx=%" PRIu32 " rx=%" PRIu32 " lost=%" PRIu32
		" busy=%" PRIu32 " missed=%" PRIu32 " err=%" PRIu32
		" rejected=%" PRIu32 " ctrl_fail=%" PRIu32 " ctrl_overflow=%"
		PRIu32 " uart_err=%" PRIu32 " uart_abort=%ld\r\n",
		role, (now_us - started_us) / 1000000ULL, state_name(link.state), link.run_id,
		elapsed_us / 1000U, tx_rate, rx_rate, counters.tx_sent,
		counters.rx_received, counters.rx_missing, counters.tx_busy,
		counters.tx_missed, counters.tx_errors, link.rejected_packets,
		link.control_tx_failures, link.control_queue_overflows,
		tx_submit_errors, (long)atomic_get(&tx_aborts));
	if (send_line(length)) {
		previous_time_us = now_us;
		previous_tx_total = counters.tx_total;
		previous_rx_total = counters.rx_total;
	}
}
```
